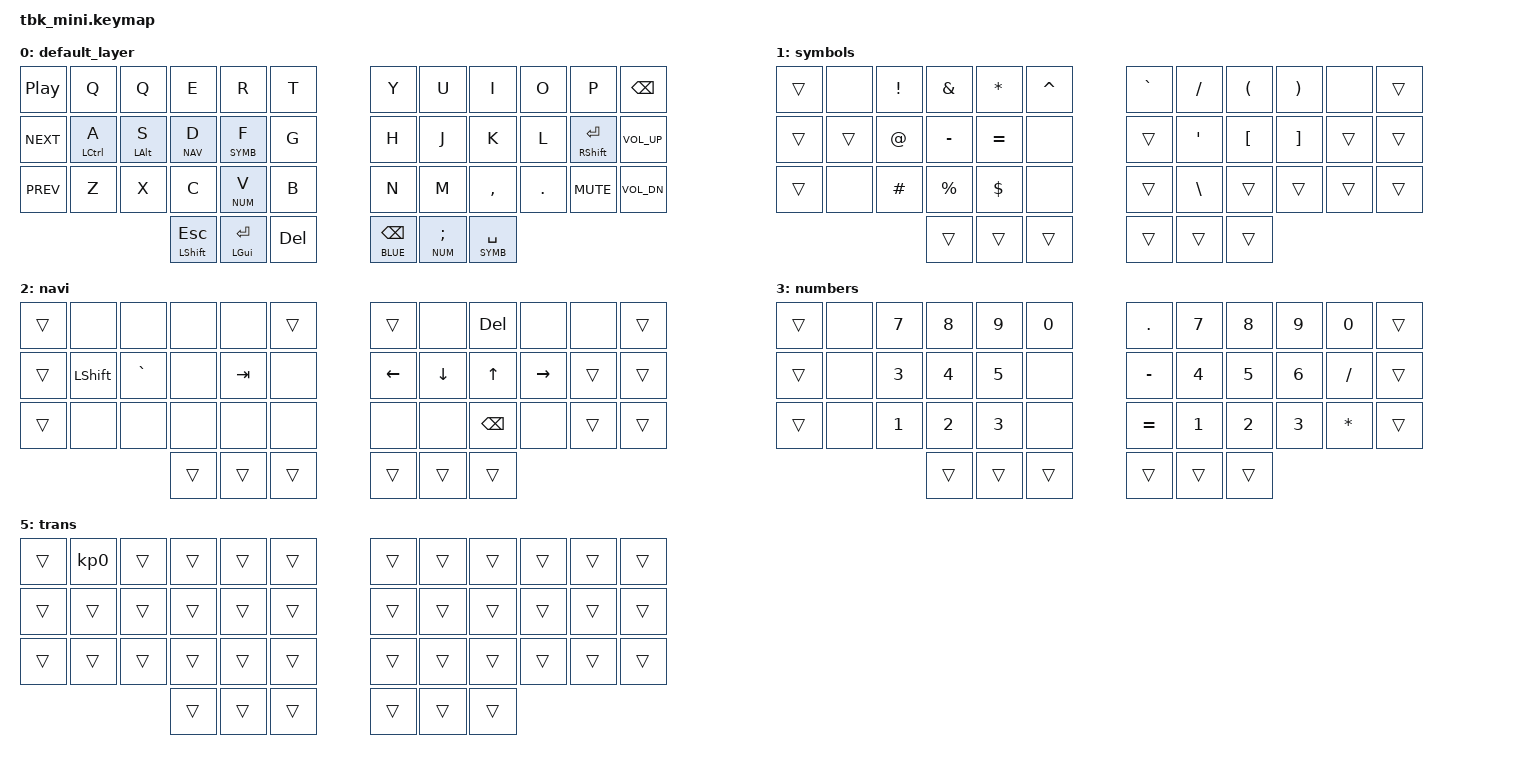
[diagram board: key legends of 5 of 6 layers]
#include <behaviors.dtsi>
#include <dt-bindings/zmk/keys.h>
#include <dt-bindings/zmk/bt.h>

#define DEFAULT 0
#define SYMB    1
#define NAV     2
#define NUM     3
#define BLUE    4

/ {

    behaviors {
        hm: homerow_mods {
            compatible = "zmk,behavior-hold-tap";
            label = "HOMEROW_MODS";
            #binding-cells = <2>;
            tapping-term-ms = <150>;
            quick_tap_ms = <0>;
            flavor = "tap-preferred";
            bindings = <&kp>, <&kp>;
        };
    };
    keymap {
        compatible = "zmk,keymap";

        default_layer {
            bindings = <
    &kp C_PP     &kp Q       &kp Q      &kp E     &kp R          &kp T           &kp Y     &kp U     &kp I     &kp O     &kp P           &kp BSPC
    &kp C_NEXT   &hm LCTRL A &hm LALT S &lt NAV D     &lt SYMB F     &kp G       &kp H     &kp J     &kp K     &kp L     &hm RSHFT ENTER &kp C_VOL_UP
    &kp C_PREV   &kp Z       &kp X      &kp C         &lt NUM V      &kp B       &kp N     &kp M     &kp COMMA &kp DOT   &kp C_MUTE      &kp C_VOL_DN
                                        &hm LSHFT ESC &hm LGUI ENTER &kp DEL    &lt BLUE BSPC &lt NUM SEMI &lt SYMB SPC 
            >;
        };

        symbols {
            bindings = <
    &trans    &none     &kp EXCL  &kp AMPS  &kp STAR  &kp CARET                     &kp GRAVE &kp FSLH  &kp LPAR  &kp RPAR  &none  &trans 
    &trans    &trans    &kp AT    &kp MINUS &kp EQUAL &none                         &trans    &kp SQT   &kp LBKT  &kp RBKT  &trans &trans
    &trans    &none     &kp HASH  &kp PRCNT &kp DLLR  &none                         &trans    &kp BSLH  &trans    &trans    &trans &trans
                                  &trans    &trans    &trans                        &trans    &trans    &trans
            >;
        };

        navi {
            bindings = <
    &trans &none     &none     &none     &none     &trans                        &trans    &none     &kp DEL   &none     &none  &trans 
    &trans &kp LSHFT &kp GRAVE &none     &kp TAB   &none                         &kp LEFT  &kp DOWN  &kp UP    &kp RIGHT &trans &trans 
    &trans &none     &none     &none     &none     &none                         &none     &none     &kp BSPC  &none     &trans &trans 
                               &trans    &trans    &trans                        &trans    &trans    &trans
            >;
        };

        numbers {
            bindings = <
    &trans &none     &kp N7    &kp N8    &kp N9    &kp N0                        &kp DOT   &kp N7    &kp N8    &kp N9    &kp N0   &trans 
    &trans &none     &kp N3    &kp N4    &kp N5    &none                         &kp MINUS &kp N4    &kp N5    &kp N6    &kp FSLH &trans 
    &trans &none     &kp N1    &kp N2    &kp N3    &none                         &kp EQUAL &kp N1    &kp N2    &kp N3    &kp STAR &trans 
                               &trans    &trans    &trans                        &trans    &trans    &trans
            >;
        };

        blue {
// I added a zero key because Zephyr won't compile with a only-transparent layer
            bindings = <
    &trans    &trans    &trans    &trans    &trans                        &bt BT_CLR    &trans    &trans    &trans    &trans
    &trans    &trans    &trans    &trans    &trans                        &bt BT_SEL 0 &bt BT_SEL 1 &bt BT_SEL 2 &bt BT_SEL 3 &bt BT_SEL 4
    &trans    &trans    &trans    &trans    &trans                        &trans    &trans    &trans    &trans    &trans
                        &trans    &trans    &trans                        &trans    &trans    &trans
            >;
        };

        // This layer is for easier copy/paste when creating new keymaps, so you have transparent keys already added
        trans {
// -------------------------------------------------------------------------------------------------------------------------
// |         |         |         |         |         |                   |         |         |         |         |         |
// |         |         |         |         |         |                   |         |         |         |         |         |
// |         |         |         |         |         |                   |         |         |         |         |         |
//           |         |         |                                                           |         |         |
//                               |         |         |                   |         |         |
//                                         |         |         |         |         |
//                                         |         |         |         |         |
// I added a zero key because Zephyr won't compile with a only-transparent layer
            bindings = <
   &trans &kp KP_N0 &trans    &trans    &trans    &trans                        &trans    &trans    &trans    &trans    &trans &trans 
   &trans &trans    &trans    &trans    &trans    &trans                        &trans    &trans    &trans    &trans    &trans &trans 
   &trans &trans    &trans    &trans    &trans    &trans                        &trans    &trans    &trans    &trans    &trans &trans 
                              &trans    &trans    &trans                        &trans    &trans    &trans
            >;
        };
    };
};
